# f29h85x_esm_system_regs register map
Vendor: Texas Instruments
Peripheral module from a debugger description file (folder C29).
Registers are 32-bit, read-write, no defined reset value unless marked. A register's access mark holds for its fields unless they carry their own. Offsets are as the file gives them; lines under a group give offsets from that group; [hi:lo] are bit positions; {n}, {i} and the like mark numbered series; 'fields as' and 'values as' point back to an identical list; <NAME> marks a mode.

## ESM_SYSTEM_REGS — ESM SYSTEM Registers
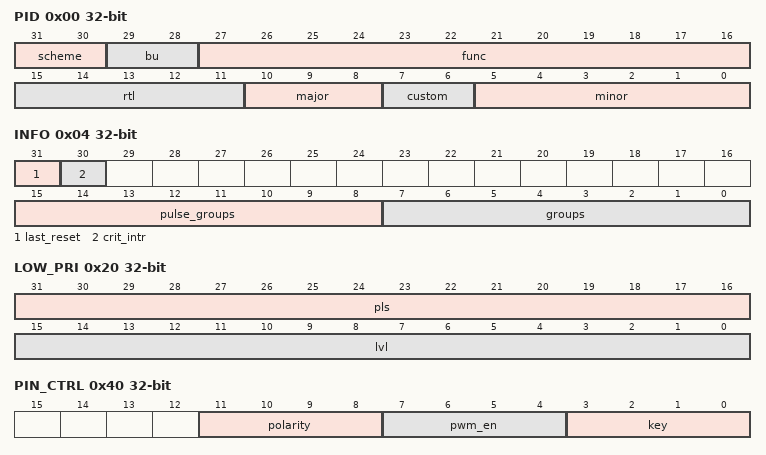
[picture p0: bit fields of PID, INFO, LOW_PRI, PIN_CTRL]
0x00 PID ro — Revision Register
  [31:30] scheme, [29:28] bu, [27:16] func, [15:11] rtl, [10:8] major, [7:6] custom, [5:0] minor
0x04 INFO ro
  [31] last_reset, [30] crit_intr, [15:8] pulse_groups, [7:0] groups
0x08 EN — Global Enable Register
  [3:0] key
0x0C SFT_RST — Global Soft Reset Register
  [3:0] key
0x20 LOW_PRI ro — Low Priority Prioritized Register
  [31:16] pls, [15:0] lvl
0x28 LOW ro — Low Priority Interrupt Status Register
  [31:0] sts
0x30 EOI — EOI Interrupt Register
  [10:0] key
0x40 PIN_CTRL — Error Pin Control Register
  [11:8] polarity, [7:4] pwm_en, [3:0] key
0x44 PIN_STS ro — Error Pin Status Register
  [0] val
0x48 PIN_CNTR ro — Error Pin Counter Value Register
  [23:0] count
0x4C PIN_CNTR_PRE — Error Pin Counter Value Pre-Load Register
  [23:0] count
0x50 PWMH_PIN_CNTR ro — Error Pin PWM High Counter Value Register
  [23:0] count
0x54 PWMH_PIN_CNTR_PRE — Error Pin PWM High Counter Value Pre-Load Register
  [23:0] count
0x58 PWML_PIN_CNTR ro — Error Pin PWM Low Counter Value Register
  [23:0] count
0x5C PWML_PIN_CNTR_PRE — Error Pin PWM Low Counter Value Pre-Load Register
  [23:0] count
0xA0 ERRPIN_MON_CFG — Error Pin Monitor Config Register
  [3:0] mon_en
0xA4 ERRPIN_MON_INTR_SET — Error Pin Monitor Interrupt Status/Set Register
  [0] val
0xA8 ERRPIN_MON_INTR_CLR — Error Pin Monitor Interrupt Status/Clear Register
  [0] val
0x100 GROUP_N_LOCK — Group N Interrupt Lock Register
0x104 GROUP_N_COMMIT — Group N Interrupt Commit Register
0x110 ERR_PIN_INFLUENCE_LOCK — Error Pin Influence Lock Register
0x114 ERR_PIN_INFLUENCE_COMMIT — Error Pin Influence Commit Register
0x118 CRI_PRI_INFLUENCE_LOCK — Critical Prioirty Interrupt Influence Lock Register
0x11C CRI_PRI_INFLUENCE_COMMIT — Critical Priority Interrupt Influence Lock Register
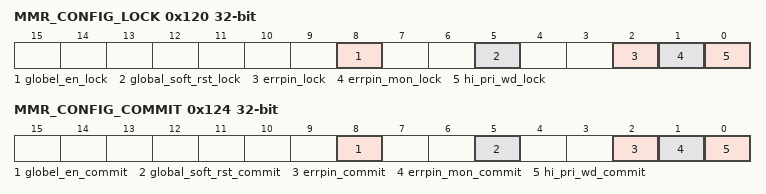
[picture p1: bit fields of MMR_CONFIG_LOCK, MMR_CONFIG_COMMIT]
0x120 MMR_CONFIG_LOCK
  [8] globel_en_lock, [5] global_soft_rst_lock, [2] errpin_lock, [1] errpin_mon_lock, [0] hi_pri_wd_lock
0x124 MMR_CONFIG_COMMIT
  [8] globel_en_commit, [5] global_soft_rst_commit, [2] errpin_commit, [1] errpin_mon_commit, [0] hi_pri_wd_commit
{0x400+0x20*i} ERR_GRP[{i}] (i=0..7) group
  0x00 RAW — Error Group N Event Raw Status/Set Register
    [31:0] sts
  0x04 STS — Error Group N Interrupt Enable Status/Clear Register
    [31:0] msk
  0x08 INTR_EN_SET — Error Group N Interrupt Enable Set Register
    [31:0] msk
  0x0C INTR_EN_CLR — Error Group N Interrupt Enabled Clear Register
    [31:0] msk
  0x10 INT_PRIO — Error Group N Interrupt Priority Register
    [31:0] msk
  0x14 PIN_EN_SET — Error Group N Error Pin Influence Set Register
    [31:0] msk
  0x18 PIN_EN_CLR — Error Group N Error Pin Influence Clear Register
    [31:0] msk
{0x800+0x20*i} ERR_EXT_GRP[{i}] (i=0..7) group
  0x00 CRIT_EN_SET — Error Group N Critical Priority Interrupt Influence Set Register
    [31:0] msk
  0x04 CRIT_EN_CLR — Error Group N Critical Priority Interrupt Influence Clear Register
    [31:0] msk
